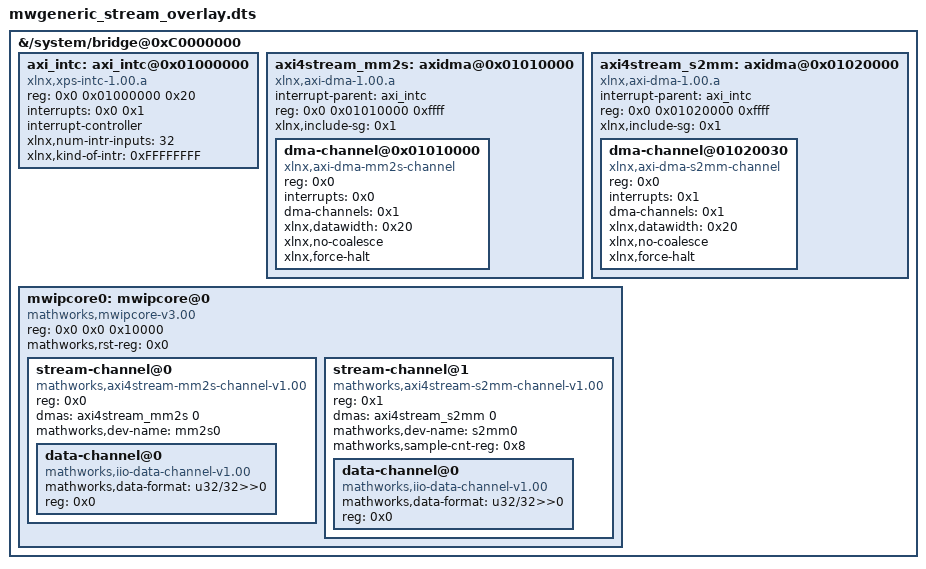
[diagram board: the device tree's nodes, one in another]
/dts-v1/;
/plugin/;

/{

	fragment {
		target-path = "/system/bridge@0xC0000000";
		/* suppress DTC warning */
		#address-cells = <2>;
		#size-cells = <1>;

		__overlay__ {
			/* suppress DTC warning */
			#address-cells = <2>;
			#size-cells = <1>;

			axi_intc:axi_intc@0x01000000 {
				compatible = "xlnx,xps-intc-1.00.a";
				reg = <0x0 0x01000000 0x20>;
				interrupts = <0x0 0x1>;
				interrupt-controller;
				#interrupt-cells = <0x1>;
				xlnx,num-intr-inputs = <32>;
				xlnx,kind-of-intr = <0xFFFFFFFF>;
			};

			axi4stream_mm2s:axidma@0x01010000 {
				#dma-cells = <0x1>;
				#address-cells = <1>;
				#size-cells = <0>;
				interrupt-parent = <&axi_intc>;
				compatible = "xlnx,axi-dma-1.00.a";
				reg = <0x0 0x01010000 0xffff>;
				xlnx,include-sg = <0x1>;
				dma-channel@0x01010000  {
					reg = <0x0>;
					compatible = "xlnx,axi-dma-mm2s-channel";
					interrupts = <0x0>;
					dma-channels = <0x1>;
					xlnx,datawidth = <0x20>;
					xlnx,no-coalesce;
					xlnx,force-halt;
				};
			};
			axi4stream_s2mm:axidma@0x01020000 {
				#dma-cells = <0x1>;
				#address-cells = <1>;
				#size-cells = <0>;
				interrupt-parent = <&axi_intc>;
				compatible = "xlnx,axi-dma-1.00.a";
				reg = <0x0 0x01020000 0xffff>;
				xlnx,include-sg = <0x1>;
				dma-channel@01020030 {
					reg = <0x0>;
					compatible = "xlnx,axi-dma-s2mm-channel";
					interrupts = <0x1>;
					dma-channels = <0x1>;			
					xlnx,datawidth = <0x20>;
					xlnx,no-coalesce;
					xlnx,force-halt;
				};
			};

			mwipcore0: mwipcore@0 {
				compatible = "mathworks,mwipcore-v3.00";
				reg = <0x0 0x0 0x10000>;
				mathworks,rst-reg = <0x0>;
				#address-cells = <1>;
				#size-cells = <0>;
				stream-channel@0 {			
					#address-cells = <1>;
					#size-cells = <0>;
					reg = <0x0>;
					compatible = "mathworks,axi4stream-mm2s-channel-v1.00";
					dma-names = "mm2s";
					dmas = <&axi4stream_mm2s 0>;
					mathworks,dev-name = "mm2s0";

					data-channel@0 {
						compatible = "mathworks,iio-data-channel-v1.00";
						mathworks,data-format = "u32/32>>0";
						reg = <0x0>;
					};
				};
				stream-channel@1 {
					reg = <0x1>;
					#address-cells = <1>;
					#size-cells = <0>;
					compatible = "mathworks,axi4stream-s2mm-channel-v1.00";
					dma-names = "s2mm";
					dmas = <&axi4stream_s2mm 0>;
					mathworks,dev-name = "s2mm0";
					mathworks,sample-cnt-reg = <0x8>;

					data-channel@0 {
						compatible = "mathworks,iio-data-channel-v1.00";
						mathworks,data-format = "u32/32>>0";
						reg = <0x0>;
					};
				};
			};
		};
	};
};
